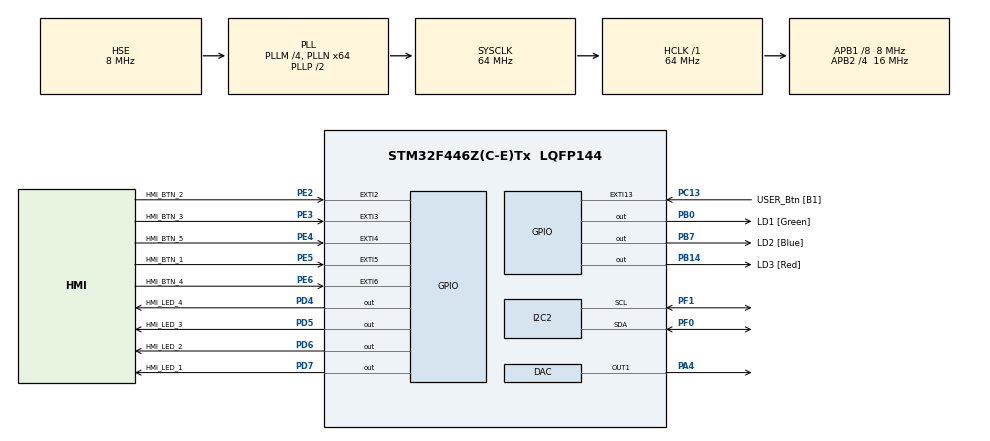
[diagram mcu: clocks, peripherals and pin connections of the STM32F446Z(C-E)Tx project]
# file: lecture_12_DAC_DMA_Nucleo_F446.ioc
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DAC.DAC_Trigger=DAC_TRIGGER_T2_TRGO
Dma.DAC1.0.Direction=DMA_MEMORY_TO_PERIPH
Dma.DAC1.0.FIFOMode=DMA_FIFOMODE_DISABLE
Dma.DAC1.0.Instance=DMA1_Stream5
Dma.DAC1.0.MemDataAlignment=DMA_MDATAALIGN_WORD
Dma.DAC1.0.MemInc=DMA_MINC_ENABLE
Dma.DAC1.0.Mode=DMA_CIRCULAR
Dma.DAC1.0.PeriphDataAlignment=DMA_PDATAALIGN_WORD
Dma.DAC1.0.PeriphInc=DMA_PINC_DISABLE
Dma.DAC1.0.Priority=DMA_PRIORITY_LOW
Dma.Request0=DAC1
Mcu.Family=STM32F4
Mcu.Name=STM32F446Z(C-E)Tx
Mcu.Package=LQFP144
NVIC.DMA1_Stream5_IRQn=true\:0\:0\:false\:false\:true\:false\:true\:true
NVIC.EXTI15_10_IRQn=true\:0\:0\:false\:false\:true\:true\:true\:true
NVIC.EXTI2_IRQn=true\:0\:0\:false\:false\:true\:true\:true\:true
NVIC.EXTI3_IRQn=true\:0\:0\:false\:false\:true\:true\:true\:true
NVIC.EXTI4_IRQn=true\:0\:0\:false\:false\:true\:true\:true\:true
NVIC.EXTI9_5_IRQn=true\:0\:0\:false\:false\:true\:true\:true\:true
NVIC.PriorityGroup=NVIC_PRIORITYGROUP_4
PA13.Mode=Serial_Wire
PA13.Signal=SYS_JTMS-SWDIO
PA14.Mode=Serial_Wire
PA14.Signal=SYS_JTCK-SWCLK
PA4.Signal=COMP_DAC1_group
PB0.GPIO_Label=LD1 [Green]
PB0.Signal=GPIO_Output
PB14.GPIO_Label=LD3 [Red]
PB14.Signal=GPIO_Output
PB7.GPIO_Label=LD2 [Blue]
PB7.Signal=GPIO_Output
PC13.GPIO_Label=USER_Btn [B1]
PC13.Signal=GPXTI13
PC14-OSC32_IN.Mode=LSE-External-Oscillator
PC14-OSC32_IN.Signal=RCC_OSC32_IN
PC15-OSC32_OUT.Mode=LSE-External-Oscillator
PC15-OSC32_OUT.Signal=RCC_OSC32_OUT
PD4.GPIO_Label=HMI_LED_4
PD4.GPIO_ModeDefaultOutputPP=GPIO_MODE_OUTPUT_PP
PD4.GPIO_PuPd=GPIO_NOPULL
PD4.GPIO_Speed=GPIO_SPEED_FREQ_LOW
PD4.PinState=GPIO_PIN_RESET
PD4.Signal=GPIO_Output
PD5.GPIO_Label=HMI_LED_3
PD5.GPIO_ModeDefaultOutputPP=GPIO_MODE_OUTPUT_PP
PD5.GPIO_PuPd=GPIO_NOPULL
PD5.GPIO_Speed=GPIO_SPEED_FREQ_LOW
PD5.PinState=GPIO_PIN_RESET
PD5.Signal=GPIO_Output
PD6.GPIO_Label=HMI_LED_2
PD6.GPIO_ModeDefaultOutputPP=GPIO_MODE_OUTPUT_PP
PD6.GPIO_PuPd=GPIO_NOPULL
PD6.GPIO_Speed=GPIO_SPEED_FREQ_LOW
PD6.PinState=GPIO_PIN_RESET
PD6.Signal=GPIO_Output
PD7.GPIO_Label=HMI_LED_1
PD7.GPIO_ModeDefaultOutputPP=GPIO_MODE_OUTPUT_PP
PD7.GPIO_PuPd=GPIO_NOPULL
PD7.GPIO_Speed=GPIO_SPEED_FREQ_LOW
PD7.PinState=GPIO_PIN_RESET
PD7.Signal=GPIO_Output
PE2.GPIO_Label=HMI_BTN_2
PE2.GPIO_ModeDefaultEXTI=GPIO_MODE_IT_RISING_FALLING
PE2.Signal=GPXTI2
PE3.GPIO_Label=HMI_BTN_3
PE3.GPIO_ModeDefaultEXTI=GPIO_MODE_IT_RISING_FALLING
PE3.Signal=GPXTI3
PE4.GPIO_Label=HMI_BTN_5
PE4.GPIO_ModeDefaultEXTI=GPIO_MODE_IT_RISING_FALLING
PE4.Signal=GPXTI4
PE5.GPIO_Label=HMI_BTN_1
PE5.GPIO_ModeDefaultEXTI=GPIO_MODE_IT_RISING_FALLING
PE5.Signal=GPXTI5
PE6.GPIO_Label=HMI_BTN_4
PE6.GPIO_ModeDefaultEXTI=GPIO_MODE_IT_RISING_FALLING
PE6.Signal=GPXTI6
PF0.Mode=I2C
PF0.Signal=I2C2_SDA
PF1.Mode=I2C
PF1.Signal=I2C2_SCL
PH0-OSC_IN.Mode=HSE-External-Clock-Source
PH0-OSC_IN.Signal=RCC_OSC_IN
PH1-OSC_OUT.Mode=HSE-External-Clock-Source
PH1-OSC_OUT.Signal=RCC_OSC_OUT
ProjectManager.HeapSize=0x200
ProjectManager.StackSize=0x400
ProjectManager.TargetToolchain=STM32CubeIDE
RCC.48MHZClocksFreq_Value=24000000
RCC.AHBFreq_Value=64000000
RCC.APB1CLKDivider=RCC_HCLK_DIV8
RCC.APB1Freq_Value=8000000
RCC.APB1TimFreq_Value=16000000
RCC.APB2CLKDivider=RCC_HCLK_DIV4
RCC.APB2Freq_Value=16000000
RCC.APB2TimFreq_Value=32000000
RCC.CortexFreq_Value=64000000
RCC.HCLKFreq_Value=64000000
RCC.HSE_VALUE=8000000
RCC.HSI_VALUE=16000000
RCC.PLLM=4
RCC.PLLMUL=RCC_PLL_MUL9
RCC.PLLN=64
RCC.PLLQ=7
RCC.PLLSourceVirtual=RCC_PLLSOURCE_HSE
RCC.PRESCALERUSB=RCC_USBCLKSOURCE_PLL_DIV1_5
RCC.SYSCLKFreq_VALUE=64000000
RCC.SYSCLKSource=RCC_SYSCLKSOURCE_PLLCLK
RCC.SYSCLKSourceVirtual=RCC_SYSCLKSOURCE_PLLCLK
RCC.USBFreq_Value=18285714.285714287
RCC.VCOOutputFreq_Value=128000000
SH.COMP_DAC1_group.0=DAC_OUT1,DAC_OUT1
TIM2.Period=999
TIM2.Prescaler=15
TIM2.TIM_MasterOutputTrigger=TIM_TRGO_UPDATE
VP_TIM2_VS_ClockSourceINT.Mode=Internal
board=NUCLEO-F446ZE

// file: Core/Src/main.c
/* USER CODE BEGIN Header */
/**
  ******************************************************************************
  * @file           : main.c
  * @brief          : Main program body
  ******************************************************************************
  * @attention
  *
  * Copyright (c) 2024 STMicroelectronics.
  * All rights reserved.
*shbdskadbsa
  *
  * This software is licensed under terms that can be found in the LICENSE file
  * in the root directory of this software component.
  * If no LICENSE file comes with this software, it is provided AS-IS.
  *
  ******************************************************************************
  */
/* USER CODE END Header */
#include "main.h"
#include "dac.h"
#include "dma.h"
#include "i2c.h"
#include "tim.h"
#include "gpio.h"

/* USER CODE BEGIN Includes */
/* Add the math library */
#include "math.h"
#include "OLED.h"
#include "stdio.h"
/* USER CODE END Includes */

void SystemClock_Config(void);

/* USER CODE BEGIN 0 */
// Sine generation function
//void GenerateSine (uint32_t* sine,uint32_t length)
//{
// // Generate a specified number of points
// for (int i=0; i<length; i++)
// {
//	 // Calculate the values for the given points
//	 sine[i] = ((sin(i*2*M_PI/length) + 1)*(4095/2));
// }
//}
/* USER CODE END 0 */
//commit
void GenerateSquare(uint32_t* square, uint32_t length, uint32_t duty)
{
  uint32_t high_points = (length * duty) / 100;

  for (uint32_t i = 0; i < length; i++)
  {
    square[i] = (i < high_points) ? 4095 : 0;   // 4095 = 3,3 V, 0 = 0 V
  }
}
int main(void)
{

  /* MCU Configuration--------------------------------------------------------*/

  /* Reset of all peripherals, Initializes the Flash interface and the Systick. */
  HAL_Init();

  /* Configure the system clock */
  SystemClock_Config();

  /* Initialize all configured peripherals */
  MX_GPIO_Init();
  MX_DMA_Init();
  MX_TIM2_Init();
  MX_DAC_Init();
  MX_I2C2_Init();
  /* USER CODE BEGIN 2 */

  /* array to store the point of the sine wave */
//  uint32_t sine_data[100];
//  /* Calculate the points of the sine wave */
//  GenerateSine(sine_data,100);
//  /* Start the DAC with DMA support */
//  HAL_DAC_Start_DMA(&hdac, DAC1_CHANNEL_1, sine_data, 100, DAC_ALIGN_12B_R);
//  /* Starting the timer2 */
//  HAL_TIM_Base_Start(&htim2);

  uint32_t square_data[100];
  GenerateSquare(square_data, 100, 50);   // 50% kitöltés

  HAL_DAC_Start_DMA(&hdac, DAC1_CHANNEL_1, square_data, 100, DAC_ALIGN_12B_R);
  HAL_TIM_Base_Start(&htim2);

  /* USER CODE END 2 */

  /* Infinite loop */
  while (1)
  {

  }
}

void SystemClock_Config(void)
{
  RCC_OscInitTypeDef RCC_OscInitStruct = {0};
  RCC_ClkInitTypeDef RCC_ClkInitStruct = {0};

  /** Configure the main internal regulator output voltage
  */
  __HAL_RCC_PWR_CLK_ENABLE();
  __HAL_PWR_VOLTAGESCALING_CONFIG(PWR_REGULATOR_VOLTAGE_SCALE3);

  /** Initializes the RCC Oscillators according to the specified parameters
  * in the RCC_OscInitTypeDef structure.
  */
  RCC_OscInitStruct.OscillatorType = RCC_OSCILLATORTYPE_HSE;
  RCC_OscInitStruct.HSEState = RCC_HSE_BYPASS;
  RCC_OscInitStruct.PLL.PLLState = RCC_PLL_ON;
  RCC_OscInitStruct.PLL.PLLSource = RCC_PLLSOURCE_HSE;
  RCC_OscInitStruct.PLL.PLLM = 4;
  RCC_OscInitStruct.PLL.PLLN = 64;
  RCC_OscInitStruct.PLL.PLLP = RCC_PLLP_DIV2;
  RCC_OscInitStruct.PLL.PLLQ = 7;
  RCC_OscInitStruct.PLL.PLLR = 2;
  if (HAL_RCC_OscConfig(&RCC_OscInitStruct) != HAL_OK)
  {
    Error_Handler();
  }

  /** Initializes the CPU, AHB and APB buses clocks
  */
  RCC_ClkInitStruct.ClockType = RCC_CLOCKTYPE_HCLK|RCC_CLOCKTYPE_SYSCLK
                              |RCC_CLOCKTYPE_PCLK1|RCC_CLOCKTYPE_PCLK2;
  RCC_ClkInitStruct.SYSCLKSource = RCC_SYSCLKSOURCE_PLLCLK;
  RCC_ClkInitStruct.AHBCLKDivider = RCC_SYSCLK_DIV1;
  RCC_ClkInitStruct.APB1CLKDivider = RCC_HCLK_DIV8;
  RCC_ClkInitStruct.APB2CLKDivider = RCC_HCLK_DIV4;

  if (HAL_RCC_ClockConfig(&RCC_ClkInitStruct, FLASH_LATENCY_2) != HAL_OK)
  {
    Error_Handler();
  }
}

void Error_Handler(void)
{
  __disable_irq();
  while (1)
  {
  }
}
